AUTOSAR XML (schema 4-0-3)
package /ComponentTypes
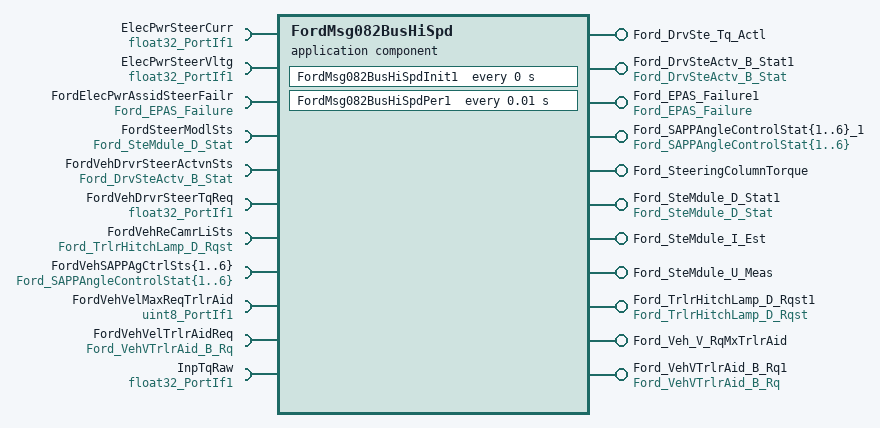
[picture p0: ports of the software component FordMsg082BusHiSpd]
  application sw component type FordMsg082BusHiSpd
    16 x provide port:
      Ford_DrvSte_Tq_Actl: nonqueued-sender-com-spec{data-element=Ford_DrvSte_Tq_Actl, init-value=0}, provided-interface=Ford_DrvSte_Tq_Actl
      Ford_DrvSteActv_B_Stat1: nonqueued-sender-com-spec{data-element=Ford_DrvSteActv_B_Stat, init-value=0}, provided-interface=Ford_DrvSteActv_B_Stat
      Ford_EPAS_Failure1: nonqueued-sender-com-spec{data-element=Ford_EPAS_Failure, init-value=0}, provided-interface=Ford_EPAS_Failure
      Ford_SAPPAngleControlStat{1..6}_1: nonqueued-sender-com-spec{data-element=Ford_SAPPAngleControlStat{1..6}, init-value=0}, provided-interface=Ford_SAPPAngleControlStat{1..6}
      Ford_SteeringColumnTorque: nonqueued-sender-com-spec{data-element=Ford_SteeringColumnTorque, init-value=255}, provided-interface=Ford_SteeringColumnTorque
      Ford_SteMdule_D_Stat1: nonqueued-sender-com-spec{data-element=Ford_SteMdule_D_Stat, init-value=0}, provided-interface=Ford_SteMdule_D_Stat
      Ford_SteMdule_I_Est: nonqueued-sender-com-spec{data-element=Ford_SteMdule_I_Est, init-value=4095}, provided-interface=Ford_SteMdule_I_Est
      Ford_SteMdule_U_Meas: nonqueued-sender-com-spec{data-element=Ford_SteMdule_U_Meas, init-value=255}, provided-interface=Ford_SteMdule_U_Meas
      Ford_TrlrHitchLamp_D_Rqst1: nonqueued-sender-com-spec{data-element=Ford_TrlrHitchLamp_D_Rqst, init-value=0}, provided-interface=Ford_TrlrHitchLamp_D_Rqst
      Ford_Veh_V_RqMxTrlrAid: nonqueued-sender-com-spec{data-element=Ford_Veh_V_RqMxTrlrAid, init-value=255}, provided-interface=Ford_Veh_V_RqMxTrlrAid
      Ford_VehVTrlrAid_B_Rq1: nonqueued-sender-com-spec{data-element=Ford_VehVTrlrAid_B_Rq, init-value=0}, provided-interface=Ford_VehVTrlrAid_B_Rq
    16 x require port:
      ElecPwrSteerCurr: nonqueued-receiver-com-spec{data-element=Val, filter=data-filter-type=ALWAYS, init-value=140.75}, required-interface=float32_PortIf1
      ElecPwrSteerVltg: nonqueued-receiver-com-spec{data-element=Val, filter=data-filter-type=ALWAYS, init-value=18.75}, required-interface=float32_PortIf1
      FordElecPwrAssidSteerFailr: nonqueued-receiver-com-spec{data-element=Ford_EPAS_Failure, filter=data-filter-type=ALWAYS, init-value=0}, required-interface=Ford_EPAS_Failure
      FordSteerModlSts: nonqueued-receiver-com-spec{data-element=Ford_SteMdule_D_Stat, filter=data-filter-type=ALWAYS, init-value=0}, required-interface=Ford_SteMdule_D_Stat
      FordVehDrvrSteerActvnSts: nonqueued-receiver-com-spec{data-element=Ford_DrvSteActv_B_Stat, filter=data-filter-type=ALWAYS, init-value=0}, required-interface=Ford_DrvSteActv_B_Stat
      FordVehDrvrSteerTqReq: nonqueued-receiver-com-spec{data-element=Val, filter=data-filter-type=ALWAYS, init-value=0}, required-interface=float32_PortIf1
      FordVehReCamrLiSts: nonqueued-receiver-com-spec{data-element=Ford_TrlrHitchLamp_D_Rqst, filter=data-filter-type=ALWAYS, init-value=0}, required-interface=Ford_TrlrHitchLamp_D_Rqst
      FordVehSAPPAgCtrlSts{1..6}: nonqueued-receiver-com-spec{data-element=Ford_SAPPAngleControlStat{1..6}, filter=data-filter-type=ALWAYS, init-value=0}, required-interface=Ford_SAPPAngleControlStat{1..6}
      FordVehVelMaxReqTrlrAid: nonqueued-receiver-com-spec{data-element=Val, filter=data-filter-type=ALWAYS, init-value=255}, required-interface=uint8_PortIf1
      FordVehVelTrlrAidReq: nonqueued-receiver-com-spec{data-element=Ford_VehVTrlrAid_B_Rq, filter=data-filter-type=ALWAYS, init-value=0}, required-interface=Ford_VehVTrlrAid_B_Rq
      InpTqRaw: nonqueued-receiver-com-spec{data-element=Val, filter=data-filter-type=ALWAYS, init-value=7.875}, required-interface=float32_PortIf1
    behavior FordMsg082BusHiSpd_InternalBehavior
      timing event FordMsg082BusHiSpdInit1_InitEvent: start-on-event=FordMsg082BusHiSpdInit1, period=0
      timing event TMT_FordMsg082BusHiSpdPer1: start-on-event=FordMsg082BusHiSpdPer1, period=0.01
      port-api-options:
        enable-take-address=false, indirect-api=false, port=Ford_DrvSte_Tq_Actl
        enable-take-address=false, indirect-api=false, port=Ford_SteeringColumnTorque
        enable-take-address=false, indirect-api=false, port=Ford_SteMdule_I_Est
        enable-take-address=false, indirect-api=false, port=Ford_SteMdule_U_Meas
        enable-take-address=false, indirect-api=false, port=Ford_Veh_V_RqMxTrlrAid
      runnable FordMsg082BusHiSpdInit1
      runnable FordMsg082BusHiSpdPer1
        data-receive-point-by-arguments:
          16 x access:
            REC_ElecPwrSteerCurr_Val: accessed-variable=ElecPwrSteerCurr.Val
            REC_ElecPwrSteerVltg_Val: accessed-variable=ElecPwrSteerVltg.Val
            REC_Ford_SteMdule_D_Stat_Ford_SteMdule_D_Stat: accessed-variable=FordSteerModlSts.Ford_SteMdule_D_Stat
            REC_FordElecPwrAssidSteerFailr_Ford_EPAS_Failure: accessed-variable=FordElecPwrAssidSteerFailr.Ford_EPAS_Failure
            REC_FordVehDrvrSteerActvnSts_Ford_DrvSteActv_B_Stat: accessed-variable=FordVehDrvrSteerActvnSts.Ford_DrvSteActv_B_Stat
            REC_FordVehDrvrSteerTqReq_Val: accessed-variable=FordVehDrvrSteerTqReq.Val
            REC_FordVehReCamrLiSts_Ford_TrlrHitchLamp_D_Rqst: accessed-variable=FordVehReCamrLiSts.Ford_TrlrHitchLamp_D_Rqst
            REC_FordVehSAPPAgCtrlSts{1..6}_Ford_SAPPAngleControlStat{1..6}: accessed-variable=FordVehSAPPAgCtrlSts{1..6}.Ford_SAPPAngleControlStat{1..6}
            REC_FordVehVelMaxReqTrlrAid_Val: accessed-variable=FordVehVelMaxReqTrlrAid.Val
            REC_FordVehVelTrlrAidReq_Ford_VehVTrlrAid_B_Rq: accessed-variable=FordVehVelTrlrAidReq.Ford_VehVTrlrAid_B_Rq
            REC_InpTqRaw_Val: accessed-variable=InpTqRaw.Val
        data-send-points:
          16 x access:
            SEND_Ford_DrvSte_Tq_Actl_Ford_DrvSte_Tq_Actl: accessed-variable=Ford_DrvSte_Tq_Actl.Ford_DrvSte_Tq_Actl
            SEND_Ford_DrvSteActv_B_Stat1_Ford_DrvSteActv_B_Stat: accessed-variable=Ford_DrvSteActv_B_Stat1.Ford_DrvSteActv_B_Stat
            SEND_Ford_EPAS_Failure1_Ford_EPAS_Failure: accessed-variable=Ford_EPAS_Failure1.Ford_EPAS_Failure
            SEND_Ford_SAPPAngleControlStat{1..6}_1_Ford_SAPPAngleControlStat{1..6}: accessed-variable=Ford_SAPPAngleControlStat{1..6}_1.Ford_SAPPAngleControlStat{1..6}
            SEND_Ford_SteeringColumnTorque_Ford_SteeringColumnTorque: accessed-variable=Ford_SteeringColumnTorque.Ford_SteeringColumnTorque
            SEND_Ford_SteMdule_D_Stat1_Ford_SteMdule_D_Stat: accessed-variable=Ford_SteMdule_D_Stat1.Ford_SteMdule_D_Stat
            SEND_Ford_SteMdule_I_Est_Ford_SteMdule_I_Est: accessed-variable=Ford_SteMdule_I_Est.Ford_SteMdule_I_Est
            SEND_Ford_SteMdule_U_Meas_Ford_SteMdule_U_Meas: accessed-variable=Ford_SteMdule_U_Meas.Ford_SteMdule_U_Meas
            SEND_Ford_TrlrHitchLamp_D_Rqst1_Ford_TrlrHitchLamp_D_Rqst: accessed-variable=Ford_TrlrHitchLamp_D_Rqst1.Ford_TrlrHitchLamp_D_Rqst
            SEND_Ford_Veh_V_RqMxTrlrAid_Ford_Veh_V_RqMxTrlrAid: accessed-variable=Ford_Veh_V_RqMxTrlrAid.Ford_Veh_V_RqMxTrlrAid
            SEND_Ford_VehVTrlrAid_B_Rq1_Ford_VehVTrlrAid_B_Rq: accessed-variable=Ford_VehVTrlrAid_B_Rq1.Ford_VehVTrlrAid_B_Rq
  swc implementation FordMsg082BusHiSpd_Implementation: behavior=FordMsg082BusHiSpd_InternalBehavior
    code-descriptors:
      code Default: artifact-descriptors=autosar-engineering-object={short-label=Default, category=SWSRC}
